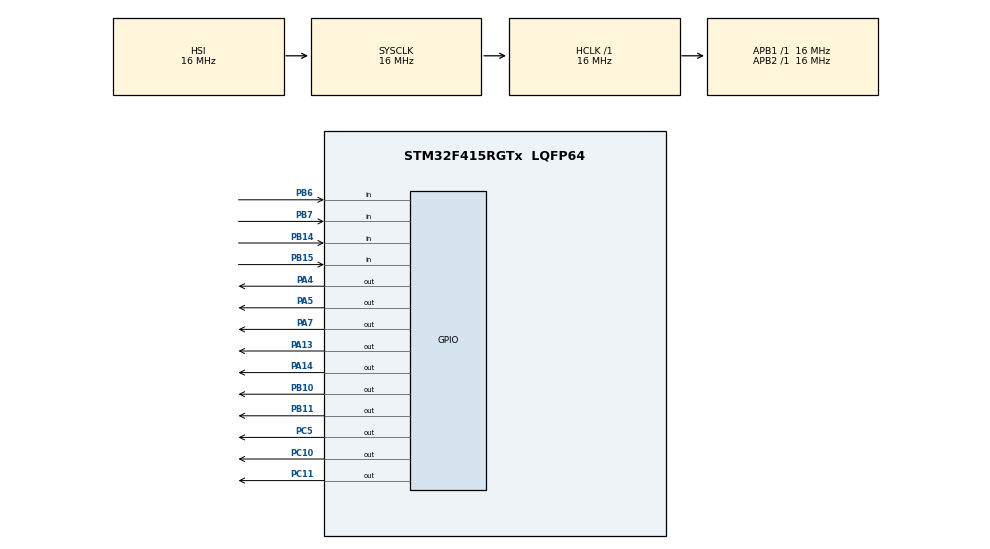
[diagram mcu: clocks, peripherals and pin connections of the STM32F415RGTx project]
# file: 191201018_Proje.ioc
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Mcu.Family=STM32F4
Mcu.Name=STM32F415RGTx
Mcu.Package=LQFP64
NVIC.PriorityGroup=NVIC_PRIORITYGROUP_4
NVIC.TIM3_IRQn=true\:0\:0\:false\:false\:true\:true\:true\:true
PA13.Signal=GPIO_Output
PA14.Signal=GPIO_Output
PA4.Signal=GPIO_Output
PA5.Signal=GPIO_Output
PA7.Signal=GPIO_Output
PB10.Signal=GPIO_Output
PB11.Signal=GPIO_Output
PB14.Signal=GPIO_Input
PB15.Signal=GPIO_Input
PB6.Signal=GPIO_Input
PB7.Signal=GPIO_Input
PC10.Signal=GPIO_Output
PC11.Signal=GPIO_Output
PC5.Signal=GPIO_Output
ProjectManager.HeapSize=0x200
ProjectManager.StackSize=0x400
ProjectManager.TargetToolchain=MDK-ARM V5.27
RCC.AHBFreq_Value=16000000
RCC.APB1Freq_Value=16000000
RCC.APB2Freq_Value=16000000
RCC.CortexFreq_Value=16000000
RCC.HSE_VALUE=25000000
RCC.HSI_VALUE=16000000
RCC.LSE_VALUE=32768
RCC.SYSCLKFreq_VALUE=16000000
RCC.VCOOutputFreq_Value=192000000
TIM3.Period=15999
TIM3.Prescaler=15999
VP_TIM3_VS_ClockSourceINT.Mode=Internal
board=custom

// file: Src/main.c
/* USER CODE BEGIN Header */
/**
 ******************************************************************************
 * @file           : main.c
 * @brief          : Main program body
 ******************************************************************************
 * @attention
 *
 * Copyright (c) 2022 STMicroelectronics.
 * All rights reserved.
 *
 * This software is licensed under terms that can be found in the LICENSE file
 * in the root directory of this software component.
 * If no LICENSE file comes with this software, it is provided AS-IS.
 *
 ******************************************************************************
 */
/* USER CODE END Header */
#include "main.h"

/* USER CODE BEGIN Includes */
#include <stdio.h>
#include <stdlib.h>
#include <stdint.h>
#include <time.h>
#include "Nokia_5110.h"
/* USER CODE END Includes */

/* USER CODE BEGIN PD */
#define R1_PORT GPIOB
#define R2_PORT GPIOB
#define R3_PORT GPIOB
#define R4_PORT GPIOB
#define R1_PIN GPIO_PIN_6
#define R2_PIN GPIO_PIN_7
#define R3_PIN GPIO_PIN_15
#define R4_PIN GPIO_PIN_14

#define C1_PORT GPIOB
#define C2_PORT GPIOB
#define C3_PORT GPIOC
#define C4_PORT GPIOC
#define C1_PIN GPIO_PIN_11
#define C2_PIN GPIO_PIN_10
#define C3_PIN GPIO_PIN_11
#define C4_PIN GPIO_PIN_10
/* USER CODE END PD */

TIM_HandleTypeDef htim3;

/* USER CODE BEGIN PV */

// #region Visuals

const unsigned char Screen_Start_Bitmap[] = {
    0x00, 0x00, 0x00, 0x00, 0x00, 0x00, 0x00, 0x00, 0x00, 0x00, 0x00, 0x00, 0x00, 0x00, 0x00, 0x00, 0x00, 0x00, 0x00, 0x00, 0x00, 0x00, 0x00, 0x00, 0x00, 0x00, 0x00, 0x00, 0x00, 0x00, 0x00, 0x00, 0x00, 0x00, 0x00, 0x00, 0x00, 0x00, 0x00, 0x00, 0x00, 0x00, 0x00, 0x00, 0x00, 0x00, 0x00, 0x00, 0x00, 0x00, 0x00, 0x00, 0x00, 0x00, 0x00, 0x00, 0x00, 0x00, 0x00, 0x00, 0x00, 0x00, 0x00, 0x00, 0x00, 0x00, 0x00, 0x00, 0x00, 0x00, 0x00, 0x00, 0x00, 0x00, 0x00, 0x00, 0x00, 0x00, 0x00, 0x00, 0x00, 0x00, 0x00, 0x00,
    0x00, 0x00, 0x00, 0x00, 0x00, 0x00, 0x00, 0x18, 0x18, 0xd8, 0xd8, 0xd8, 0xf8, 0x00, 0x20, 0xf8, 0x98, 0x98, 0x98, 0x88, 0x80, 0x00, 0x00, 0x98, 0x98, 0x98, 0x98, 0x98, 0xf8, 0x10, 0x00, 0x00, 0x00, 0x00, 0x00, 0x00, 0x00, 0x00, 0xf8, 0xd8, 0xd8, 0x98, 0xd8, 0xd8, 0x00, 0x00, 0xc0, 0x00, 0x00, 0xc0, 0x00, 0x00, 0xc0, 0xc0, 0x40, 0xc0, 0x00, 0x20, 0xf8, 0x98, 0x18, 0x00, 0xc0, 0xc0, 0xc0, 0xc0, 0x00, 0x00, 0xc0, 0xc0, 0xc0, 0xc0, 0x00, 0x00, 0xc0, 0xc0, 0xc0, 0x80, 0x00, 0x00, 0x00, 0x00, 0x00, 0x00,
    0x00, 0x00, 0x00, 0x00, 0x00, 0x00, 0x00, 0x0c, 0x0c, 0x0c, 0x04, 0x0c, 0x0f, 0x00, 0x02, 0x0f, 0x0d, 0x0d, 0x09, 0x0d, 0x0f, 0x00, 0x02, 0x0f, 0x0d, 0x0d, 0x05, 0x0d, 0x0d, 0x00, 0x00, 0x00, 0x00, 0x00, 0x00, 0x00, 0x00, 0x00, 0x0c, 0x08, 0x0c, 0x0c, 0x0d, 0x0f, 0x00, 0x00, 0x0f, 0x0c, 0x0c, 0x0f, 0x01, 0x00, 0x0f, 0x01, 0x00, 0x00, 0x00, 0x00, 0x0f, 0x01, 0x00, 0x00, 0x0f, 0x0f, 0x0f, 0x0f, 0x00, 0x00, 0x0f, 0x00, 0x00, 0x00, 0x00, 0x00, 0x0f, 0x0f, 0x0f, 0x0f, 0x00, 0x00, 0x00, 0x00, 0x00, 0x00,
    0x00, 0x00, 0x00, 0x00, 0x00, 0x00, 0x00, 0x00, 0x00, 0x00, 0x00, 0x00, 0x00, 0x00, 0x00, 0x00, 0x00, 0x00, 0x00, 0x00, 0xc0, 0xc0, 0xc0, 0xc0, 0xc0, 0x00, 0x00, 0xc0, 0xc0, 0xc0, 0xc0, 0x00, 0x00, 0xc0, 0xc0, 0xc0, 0xc0, 0x00, 0x00, 0xc0, 0xc0, 0x80, 0xc0, 0x00, 0x00, 0xc0, 0x40, 0xc0, 0xc0, 0x00, 0x00, 0x00, 0x00, 0xf8, 0x98, 0xd8, 0xd8, 0xd8, 0x00, 0x00, 0x00, 0x00, 0x00, 0x00, 0x00, 0x00, 0x00, 0x00, 0x00, 0x00, 0x00, 0x00, 0x00, 0x00, 0x00, 0x00, 0x00, 0x00, 0x00, 0x00, 0x00, 0x00, 0x00, 0x00,
    0x00, 0x00, 0x00, 0x00, 0x00, 0x00, 0x00, 0x00, 0x00, 0x00, 0x00, 0x00, 0x00, 0x00, 0x00, 0x00, 0x00, 0x00, 0x00, 0x00, 0xff, 0x1c, 0x0c, 0x08, 0x0f, 0x04, 0x01, 0x0f, 0x00, 0x00, 0x00, 0x00, 0x02, 0x0f, 0x0d, 0x0f, 0x0f, 0x00, 0x00, 0x0f, 0x0d, 0x0f, 0x0f, 0x00, 0x00, 0x0f, 0x0f, 0x0d, 0x0f, 0x00, 0x00, 0x00, 0x00, 0x0c, 0x0c, 0x0c, 0x0c, 0x0f, 0x00, 0x00, 0x00, 0x00, 0x00, 0x00, 0x00, 0x00, 0x00, 0x00, 0x00, 0x00, 0x00, 0x00, 0x00, 0x00, 0x00, 0x00, 0x00, 0x00, 0x00, 0x00, 0x00, 0x00, 0x00, 0x00,
    0x00, 0x00, 0x00, 0x00, 0x00, 0x00, 0x00, 0x00, 0x00, 0x00, 0x00, 0x00, 0x00, 0x00, 0x00, 0x00, 0x00, 0x00, 0x00, 0x00, 0x00, 0x00, 0x00, 0x00, 0x00, 0x00, 0x00, 0x00, 0x00, 0x00, 0x00, 0x00, 0x00, 0x00, 0x00, 0x00, 0x00, 0x00, 0x00, 0x00, 0x00, 0x00, 0x00, 0x00, 0x00, 0x00, 0x00, 0x00, 0x00, 0x00, 0x00, 0x00, 0x00, 0x00, 0x00, 0x00, 0x00, 0x00, 0x00, 0x00, 0x00, 0x00, 0x00, 0x00, 0x00, 0x00, 0x00, 0x00, 0x00, 0x00, 0x00, 0x00, 0x00, 0x00, 0x00, 0x00, 0x00, 0x00, 0x00, 0x00, 0x00, 0x00, 0x00, 0x00};

const unsigned char Screen_End_Fail_Bitmap[] = {
    0x00, 0x00, 0x00, 0x00, 0x00, 0x00, 0x00, 0x00, 0x00, 0x00, 0x00, 0x00, 0x00, 0x00, 0x00, 0x00, 0x00, 0x00, 0x00, 0x00, 0x00, 0x00, 0x00, 0x00, 0x00, 0x00, 0x00, 0x00, 0x00, 0x00, 0x00, 0x00, 0x00, 0x00, 0x00, 0x00, 0x00, 0x00, 0x00, 0x00, 0x00, 0x00, 0x00, 0x00, 0x00, 0x00, 0x00, 0x00, 0x00, 0x00, 0x00, 0x00, 0x00, 0x00, 0x00, 0x00, 0x00, 0x00, 0x00, 0x00, 0x00, 0x00, 0x00, 0x00, 0x00, 0x00, 0x00, 0x00, 0x00, 0x00, 0x00, 0x00, 0x00, 0x00, 0x00, 0x00, 0x00, 0x00, 0x00, 0x00, 0x00, 0x00, 0x00, 0x00,
    0x00, 0x00, 0x00, 0x00, 0x00, 0x00, 0x00, 0x00, 0x00, 0x00, 0x00, 0x00, 0x00, 0x00, 0x00, 0x00, 0x00, 0x00, 0x00, 0x00, 0x00, 0x00, 0x00, 0x00, 0x00, 0xb8, 0xa8, 0x08, 0x08, 0x08, 0x98, 0xf0, 0x00, 0xb8, 0xe8, 0x08, 0x08, 0x08, 0xd8, 0x68, 0x00, 0xb8, 0xe8, 0x08, 0x08, 0x08, 0xd8, 0x68, 0x00, 0xb8, 0xa8, 0x08, 0x08, 0x08, 0x08, 0x08, 0x00, 0x58, 0xb8, 0x00, 0x00, 0x00, 0x00, 0x00, 0x00, 0x00, 0x00, 0x00, 0x00, 0x00, 0x00, 0x00, 0x00, 0x00, 0x00, 0x00, 0x00, 0x00, 0x00, 0x00, 0x00, 0x00, 0x00, 0x00,
    0x00, 0x00, 0x00, 0x00, 0x00, 0x00, 0x00, 0x00, 0x00, 0x00, 0x00, 0x00, 0x00, 0x00, 0x00, 0x00, 0x00, 0x00, 0x00, 0x00, 0x00, 0x00, 0x00, 0x00, 0x00, 0x17, 0x1e, 0x10, 0x10, 0x10, 0x17, 0x1c, 0x00, 0x17, 0x1d, 0x10, 0x10, 0x10, 0x19, 0x1d, 0x00, 0x1e, 0x0f, 0x01, 0x01, 0x01, 0x01, 0x01, 0x00, 0x11, 0x11, 0x11, 0x11, 0x11, 0x1b, 0x1f, 0x00, 0x16, 0x13, 0x00, 0x00, 0x00, 0x00, 0x00, 0x00, 0x00, 0x00, 0x00, 0x00, 0x00, 0x00, 0x00, 0x00, 0x00, 0x00, 0x00, 0x00, 0x00, 0x00, 0x00, 0x00, 0x00, 0x00, 0x00,
    0x00, 0x00, 0x00, 0x00, 0x00, 0x00, 0x00, 0x00, 0x00, 0x00, 0x00, 0x00, 0x00, 0x00, 0xf8, 0x80, 0x80, 0x80, 0x80, 0xf8, 0x00, 0x00, 0xc0, 0x40, 0x40, 0x40, 0x40, 0xc0, 0x00, 0x00, 0xc0, 0x00, 0x00, 0x00, 0x00, 0xc0, 0x00, 0x00, 0x00, 0x00, 0x00, 0x00, 0xc0, 0x40, 0x40, 0x40, 0x40, 0xf8, 0x00, 0x00, 0xc8, 0x00, 0x00, 0xc0, 0x40, 0x40, 0x40, 0xc0, 0x00, 0x00, 0xc0, 0x40, 0x40, 0x40, 0x40, 0xf8, 0x00, 0x00, 0x00, 0x00, 0x00, 0x00, 0x00, 0x00, 0x00, 0x00, 0x00, 0x00, 0x00, 0x00, 0x00, 0x00, 0x00, 0x00,
    0x00, 0x00, 0x00, 0x00, 0x00, 0x00, 0x00, 0x00, 0x00, 0x00, 0x00, 0x00, 0x00, 0x00, 0x08, 0x08, 0x08, 0x08, 0x08, 0x0f, 0x00, 0x00, 0x0f, 0x08, 0x08, 0x08, 0x08, 0x0f, 0x00, 0x00, 0x0f, 0x08, 0x08, 0x08, 0x08, 0x0f, 0x00, 0x00, 0x00, 0x00, 0x00, 0x00, 0x0f, 0x08, 0x08, 0x08, 0x08, 0x0f, 0x00, 0x00, 0x0f, 0x00, 0x00, 0x0f, 0x09, 0x09, 0x09, 0x09, 0x00, 0x00, 0x0f, 0x08, 0x08, 0x08, 0x08, 0x0f, 0x00, 0x00, 0x0c, 0x0c, 0x00, 0x00, 0x00, 0x00, 0x00, 0x00, 0x00, 0x00, 0x00, 0x00, 0x00, 0x00, 0x00, 0x00,
    0x00, 0x00, 0x00, 0x00, 0x00, 0x00, 0x00, 0x00, 0x00, 0x00, 0x00, 0x00, 0x00, 0x00, 0x00, 0x00, 0x00, 0x00, 0x00, 0x00, 0x00, 0x00, 0x00, 0x00, 0x00, 0x00, 0x00, 0x00, 0x00, 0x00, 0x00, 0x00, 0x00, 0x00, 0x00, 0x00, 0x00, 0x00, 0x00, 0x00, 0x00, 0x00, 0x00, 0x00, 0x00, 0x00, 0x00, 0x00, 0x00, 0x00, 0x00, 0x00, 0x00, 0x00, 0x00, 0x00, 0x00, 0x00, 0x00, 0x00, 0x00, 0x00, 0x00, 0x00, 0x00, 0x00, 0x00, 0x00, 0x00, 0x00, 0x00, 0x00, 0x00, 0x00, 0x00, 0x00, 0x00, 0x00, 0x00, 0x00, 0x00, 0x00, 0x00, 0x00};

const unsigned char Screen_End_Success_Bitmap[] = {
    0x00, 0x00, 0x00, 0x00, 0x00, 0x00, 0x00, 0x00, 0x00, 0x00, 0x00, 0x00, 0x00, 0x00, 0x00, 0x00, 0x00, 0x00, 0x00, 0x00, 0x00, 0x00, 0x00, 0x00, 0x00, 0x00, 0x00, 0x00, 0x00, 0x00, 0x00, 0x00, 0x00, 0x00, 0x00, 0x00, 0x00, 0x00, 0x00, 0x00, 0x00, 0x00, 0x00, 0x00, 0x00, 0x00, 0x00, 0x00, 0x00, 0x00, 0x00, 0x00, 0x00, 0x00, 0x00, 0x00, 0x00, 0x00, 0x00, 0x00, 0x00, 0x00, 0x00, 0x00, 0x00, 0x00, 0x00, 0x00, 0x00, 0x00, 0x00, 0x00, 0x00, 0x00, 0x00, 0x00, 0x00, 0x00, 0x00, 0x00, 0x00, 0x00, 0x00, 0x00,
    0x00, 0x00, 0x00, 0x00, 0x00, 0x00, 0x00, 0x00, 0x00, 0x00, 0x00, 0x00, 0xff, 0xdf, 0x00, 0x00, 0x00, 0x00, 0x00, 0x00, 0x00, 0x00, 0x00, 0x00, 0x00, 0x00, 0x00, 0xff, 0xff, 0x00, 0x00, 0x00, 0x00, 0x00, 0x00, 0x00, 0x00, 0x00, 0x00, 0x00, 0x00, 0x00, 0x00, 0x00, 0x00, 0x00, 0x00, 0x00, 0xff, 0xf7, 0x00, 0x00, 0x00, 0x00, 0x00, 0x00, 0x00, 0x00, 0x00, 0x00, 0x00, 0x00, 0x00, 0xff, 0xff, 0x00, 0x00, 0x00, 0x00, 0xff, 0xff, 0x00, 0x00, 0x00, 0x00, 0x00, 0x00, 0x00, 0x00, 0x00, 0x00, 0x00, 0x00, 0x00,
    0x00, 0x00, 0x00, 0x00, 0x00, 0x00, 0x00, 0x00, 0x00, 0x00, 0x00, 0x00, 0xff, 0x77, 0x00, 0x00, 0x00, 0x00, 0x00, 0x00, 0x00, 0x00, 0x00, 0x00, 0x00, 0x00, 0x00, 0xff, 0xff, 0x00, 0x00, 0x00, 0xff, 0xff, 0x03, 0x01, 0x03, 0x01, 0x03, 0x01, 0x03, 0x01, 0x01, 0xff, 0xff, 0x00, 0x00, 0x00, 0xff, 0xdd, 0x00, 0x00, 0x00, 0x00, 0x00, 0x00, 0x00, 0x00, 0x00, 0x00, 0x00, 0x00, 0x00, 0xff, 0xff, 0x00, 0x00, 0x00, 0x00, 0xff, 0xff, 0x00, 0x00, 0x00, 0x00, 0x00, 0x00, 0x00, 0x00, 0x00, 0x00, 0x00, 0x00, 0x00,
    0x00, 0x00, 0x00, 0x00, 0x00, 0x00, 0x00, 0x00, 0x00, 0x00, 0x00, 0x00, 0xfe, 0x7f, 0x00, 0x00, 0x00, 0x00, 0x00, 0xfc, 0xfc, 0xfc, 0x40, 0x00, 0x00, 0x00, 0x00, 0xff, 0xff, 0x00, 0x00, 0x00, 0xff, 0x7d, 0x00, 0x00, 0x00, 0x00, 0x00, 0x00, 0x00, 0x00, 0x00, 0xff, 0xff, 0x00, 0x00, 0x00, 0xdf, 0xff, 0x00, 0x00, 0x00, 0x00, 0x00, 0xfc, 0xfc, 0xfc, 0x00, 0x00, 0x00, 0x00, 0x00, 0xff, 0xff, 0x00, 0x00, 0x00, 0x00, 0xff, 0xff, 0x00, 0x00, 0x00, 0x00, 0x00, 0x00, 0x00, 0x00, 0x00, 0x00, 0x00, 0x00, 0x00,
    0x00, 0x00, 0x00, 0x00, 0x00, 0x00, 0x00, 0x00, 0x00, 0x00, 0x00, 0x00, 0xff, 0xff, 0x80, 0xc0, 0x80, 0xc0, 0x88, 0xff, 0xff, 0xff, 0x90, 0xc0, 0x80, 0xc0, 0x80, 0xff, 0xff, 0x00, 0x00, 0x00, 0xff, 0xf7, 0xc0, 0x80, 0x80, 0xc0, 0x80, 0x80, 0xc0, 0x80, 0x80, 0xff, 0xff, 0x00, 0x00, 0x00, 0xff, 0xdf, 0x80, 0xc0, 0x80, 0xc0, 0x80, 0xff, 0xff, 0xff, 0xc4, 0x80, 0x80, 0xc0, 0x80, 0xff, 0xff, 0x00, 0x00, 0x00, 0x00, 0xf3, 0xf3, 0x00, 0x00, 0x00, 0x00, 0x00, 0x00, 0x00, 0x00, 0x00, 0x00, 0x00, 0x00, 0x00,
    0x00, 0x00, 0x00, 0x00, 0x00, 0x00, 0x00, 0x00, 0x00, 0x00, 0x00, 0x00, 0x00, 0x00, 0x00, 0x00, 0x00, 0x00, 0x00, 0x00, 0x00, 0x00, 0x00, 0x00, 0x00, 0x00, 0x00, 0x00, 0x00, 0x00, 0x00, 0x00, 0x00, 0x00, 0x00, 0x00, 0x00, 0x00, 0x00, 0x00, 0x00, 0x00, 0x00, 0x00, 0x00, 0x00, 0x00, 0x00, 0x00, 0x00, 0x00, 0x00, 0x00, 0x00, 0x00, 0x00, 0x01, 0x00, 0x00, 0x00, 0x00, 0x00, 0x00, 0x00, 0x00, 0x00, 0x00, 0x00, 0x00, 0x00, 0x00, 0x00, 0x00, 0x00, 0x00, 0x00, 0x00, 0x00, 0x00, 0x00, 0x00, 0x00, 0x00, 0x00};

// To animate success, first clear the screen, then draw the success image. Then, animate the success image by shifting it to the left and drawing it again.

const unsigned char Barrier_Jump_Bitmap[] = {
    0x00, 0x00, 0x00, 0x00, 0x00, 0x00, 0x00, 0x00, 0x00, 0x00, 0x00, 0x00, 0x00, 0xe7, 0xe7, 0x00, 0x00, 0x00, 0x00, 0x00, 0x00, 0x00, 0x00, 0x00, 0x00, 0x00, 0x00, 0x00};

const unsigned char Barrier_Solid_Bitmap[] = {
    0x00, 0x00, 0x00, 0x00, 0x00, 0x00, 0x00, 0x00, 0x00, 0x00, 0x00, 0x00, 0x00, 0xff, 0xff, 0x00, 0x00, 0x00, 0x00, 0x00, 0x00, 0x00, 0x00, 0x00, 0x00, 0x00, 0x00, 0x00};

const unsigned char Empty_Bitmap[] = {
    0x00, 0x00, 0x00, 0x00, 0x00, 0x00, 0x00, 0x00, 0x00, 0x00, 0x00, 0x00, 0x00, 0x00, 0x00, 0x00, 0x00, 0x00, 0x00, 0x00, 0x00, 0x00, 0x00, 0x00, 0x00, 0x00, 0x00, 0x00};

const unsigned char Empty_Row_Bitmap[] = {
    0x00, 0x00, 0x00, 0x00, 0x00, 0x00, 0x00, 0x00, 0x00, 0x00, 0x00, 0x00, 0x00, 0x00, 0x00, 0x00, 0x00, 0x00, 0x00, 0x00, 0x00, 0x00, 0x00, 0x00, 0x00, 0x00, 0x00, 0x00,
    0x00, 0x00, 0x00, 0x00, 0x00, 0x00, 0x00, 0x00, 0x00, 0x00, 0x00, 0x00, 0x00, 0x00, 0x00, 0x00, 0x00, 0x00, 0x00, 0x00, 0x00, 0x00, 0x00, 0x00, 0x00, 0x00, 0x00, 0x00,
    0x00, 0x00, 0x00, 0x00, 0x00, 0x00, 0x00, 0x00, 0x00, 0x00, 0x00, 0x00, 0x00, 0x00, 0x00, 0x00, 0x00, 0x00, 0x00, 0x00, 0x00, 0x00, 0x00, 0x00, 0x00, 0x00, 0x00, 0x00};

const unsigned char Player_Default_Bitmap[] = {
    0x00, 0x00, 0x00, 0x00, 0x00, 0x00, 0x00, 0x00, 0x00, 0x40, 0x60, 0x30, 0x18, 0x0c, 0x0c, 0x18, 0x30, 0x60, 0x40, 0x00, 0x00, 0x00, 0x00, 0x00, 0x00, 0x00, 0x00, 0x00};

const unsigned char Player_Jump_Bitmap[] = {
    0x00, 0x00, 0x00, 0x00, 0x40, 0x60, 0x30, 0x18, 0x0c, 0x00, 0x00, 0x00, 0x00, 0xe7, 0xe7, 0x00, 0x00, 0x00, 0x00, 0x0c, 0x18, 0x30, 0x60, 0x40, 0x00, 0x00, 0x00, 0x00};

/*ANIMATIONS*/
const unsigned char ETU_1[] = {
    0x00, 0x00, 0x00, 0x00, 0x00, 0x00, 0x00, 0x00, 0x00, 0x00, 0x00, 0x00, 0x00, 0x00, 0x00, 0x00, 0x00, 0x00, 0x00, 0x00, 0x00, 0x00, 0x00, 0x00, 0x00, 0x00, 0x00, 0x00, 0x00, 0x00, 0x00, 0x80, 0x00, 0x00, 0x20, 0x20, 0x00, 0x90, 0x80, 0x10, 0xd0, 0x00, 0x90, 0x00, 0x00, 0xd0, 0x00, 0x20, 0x20, 0x00, 0x40, 0x00, 0x80, 0x00, 0x00, 0x00, 0x00, 0x00, 0x00, 0x00, 0x00, 0x00, 0x00, 0x00, 0x00, 0x00, 0x00, 0x00, 0x00, 0x00, 0x00, 0x00, 0x00, 0x00, 0x00, 0x00, 0x00, 0x00, 0x00, 0x00, 0x00, 0x00, 0x00, 0x00,
    0x00, 0x00, 0x00, 0x00, 0x00, 0x00, 0x00, 0x00, 0x00, 0x00, 0x00, 0x00, 0x00, 0x00, 0x00, 0x00, 0x00, 0x00, 0x00, 0x00, 0x00, 0x00, 0x00, 0x00, 0x40, 0x10, 0x08, 0x04, 0x00, 0x43, 0x00, 0x00, 0x86, 0x0e, 0x07, 0x20, 0x17, 0x03, 0x02, 0x0b, 0x0a, 0x00, 0x03, 0x08, 0x0b, 0x01, 0x00, 0x16, 0x03, 0x0c, 0x97, 0x00, 0x02, 0x00, 0x42, 0x02, 0x00, 0x08, 0x20, 0x40, 0x00, 0x00, 0x00, 0x00, 0x00, 0x00, 0x00, 0x00, 0x00, 0x00, 0x00, 0x00, 0x00, 0x00, 0x00, 0x00, 0x00, 0x00, 0x00, 0x00, 0x00, 0x00, 0x00, 0x00,
    0x00, 0x00, 0x00, 0x00, 0x00, 0x00, 0x00, 0x00, 0x00, 0x00, 0x00, 0x00, 0x00, 0x00, 0x00, 0x00, 0x00, 0x00, 0x00, 0x00, 0x00, 0x00, 0xa8, 0x02, 0x00, 0xd8, 0x52, 0x10, 0x00, 0x60, 0x0c, 0x02, 0x00, 0x00, 0x00, 0x00, 0x00, 0x80, 0xe0, 0xfe, 0xff, 0x3f, 0x3f, 0xff, 0xfc, 0xe0, 0x80, 0x00, 0x00, 0x00, 0x00, 0x00, 0x02, 0x08, 0x60, 0x00, 0x00, 0xaa, 0xa8, 0x00, 0x06, 0xa0, 0x00, 0x00, 0x00, 0x00, 0x00, 0x00, 0x00, 0x00, 0x00, 0x00, 0x00, 0x00, 0x00, 0x00, 0x00, 0x00, 0x00, 0x00, 0x00, 0x00, 0x00, 0x00,
    0x00, 0x00, 0x00, 0x00, 0x00, 0x00, 0x00, 0x00, 0x00, 0x00, 0x00, 0x00, 0x00, 0x00, 0x00, 0x00, 0x00, 0x00, 0x00, 0x00, 0x00, 0x00, 0x16, 0x40, 0x00, 0x29, 0x75, 0x80, 0x00, 0x06, 0x20, 0x40, 0x00, 0x00, 0x08, 0x3e, 0x3f, 0x1f, 0x3b, 0x1b, 0x10, 0x1c, 0x18, 0x18, 0x2b, 0x3b, 0x1f, 0x7f, 0x3e, 0x3c, 0x00, 0x00, 0x80, 0x10, 0x03, 0x00, 0x60, 0x15, 0x05, 0x00, 0x80, 0x16, 0x00, 0x00, 0x00, 0x00, 0x00, 0x00, 0x00, 0x00, 0x00, 0x00, 0x00, 0x00, 0x00, 0x00, 0x00, 0x00, 0x00, 0x00, 0x00, 0x00, 0x00, 0x00,
    0x00, 0x00, 0x00, 0x00, 0x00, 0x00, 0x00, 0x00, 0x00, 0x00, 0x00, 0x00, 0x00, 0x00, 0x00, 0x00, 0x00, 0x00, 0x00, 0x00, 0x00, 0x00, 0x00, 0x00, 0x03, 0x00, 0x10, 0x00, 0x41, 0x04, 0x10, 0x08, 0x00, 0x01, 0x60, 0x94, 0x00, 0xc8, 0x00, 0x91, 0x91, 0x02, 0x91, 0x02, 0xc3, 0x80, 0x00, 0xc8, 0xc4, 0x40, 0x01, 0x24, 0x28, 0x01, 0x84, 0x42, 0x21, 0x00, 0x04, 0x01, 0x00, 0x00, 0x00, 0x00, 0x00, 0x00, 0x00, 0x00, 0x00, 0x00, 0x00, 0x00, 0x00, 0x00, 0x00, 0x00, 0x00, 0x00, 0x00, 0x00, 0x00, 0x00, 0x00, 0x00,
    0x00, 0x00, 0x00, 0x00, 0x00, 0x00, 0x00, 0x00, 0x00, 0x00, 0x00, 0x00, 0x00, 0x00, 0x00, 0x00, 0x00, 0x00, 0x00, 0x00, 0x00, 0x00, 0x00, 0x00, 0x00, 0x00, 0x00, 0x00, 0x00, 0x00, 0x00, 0x01, 0x02, 0x00, 0x00, 0x04, 0x04, 0x00, 0x09, 0x00, 0x08, 0x01, 0x09, 0x08, 0x09, 0x00, 0x08, 0x00, 0x04, 0x04, 0x02, 0x00, 0x01, 0x00, 0x00, 0x00, 0x00, 0x00, 0x00, 0x00, 0x00, 0x00, 0x00, 0x00, 0x00, 0x00, 0x00, 0x00, 0x00, 0x00, 0x00, 0x00, 0x00, 0x00, 0x00, 0x00, 0x00, 0x00, 0x00, 0x00, 0x00, 0x00, 0x00, 0x00};

const unsigned char ETU_2[] = {
    0x00, 0x00, 0x00, 0x00, 0x00, 0x00, 0x00, 0x00, 0x00, 0x00, 0x00, 0x00, 0x00, 0x00, 0x00, 0x00, 0x00, 0xc0, 0x20, 0x10, 0x08, 0x04, 0x82, 0xc1, 0xc0, 0x80, 0x18, 0xa0, 0x40, 0x00, 0x00, 0x80, 0x06, 0x82, 0x40, 0x40, 0x00, 0x20, 0x20, 0x24, 0x07, 0x20, 0x23, 0x25, 0x24, 0x26, 0x03, 0x47, 0x4b, 0x0d, 0x85, 0x98, 0x0e, 0xb7, 0x15, 0x86, 0xc0, 0x60, 0x70, 0x11, 0x21, 0x42, 0x84, 0x08, 0x10, 0x40, 0x80, 0x00, 0x00, 0x00, 0x00, 0x00, 0x00, 0x00, 0x00, 0x00, 0x00, 0x00, 0x00, 0x00, 0x00, 0x00, 0x00, 0x00,
    0x00, 0x00, 0x00, 0x00, 0x00, 0x00, 0x00, 0x00, 0x00, 0x00, 0x00, 0x00, 0x00, 0xc0, 0x18, 0x04, 0x03, 0x00, 0xc0, 0x50, 0x54, 0x2a, 0x0a, 0x00, 0x00, 0x81, 0x21, 0x10, 0x08, 0x04, 0x02, 0x01, 0x01, 0x00, 0x00, 0x00, 0x00, 0x00, 0x00, 0x00, 0x00, 0x00, 0x80, 0xe0, 0xe0, 0xe0, 0xe0, 0xe0, 0xc0, 0x80, 0x00, 0x00, 0x01, 0x02, 0x00, 0x08, 0x11, 0x61, 0x85, 0x04, 0x06, 0x73, 0x11, 0x5b, 0x0c, 0x28, 0x14, 0x03, 0x04, 0x60, 0x80, 0x00, 0x00, 0x00, 0x00, 0x00, 0x00, 0x00, 0x00, 0x00, 0x00, 0x00, 0x00, 0x00,
    0x00, 0x00, 0x00, 0x00, 0x00, 0x00, 0x00, 0x00, 0x00, 0x00, 0x00, 0x00, 0xbc, 0x01, 0x00, 0x00, 0xe8, 0x2a, 0x6a, 0x09, 0x00, 0x00, 0x00, 0x78, 0x06, 0x00, 0x00, 0x00, 0x00, 0x80, 0xa0, 0x60, 0xe0, 0xf0, 0xf0, 0xf0, 0xf8, 0xf8, 0xfc, 0x7c, 0x3f, 0x3f, 0x1f, 0x1f, 0xff, 0xff, 0xff, 0xff, 0xff, 0x07, 0x00, 0x00, 0x00, 0x00, 0x00, 0x00, 0x00, 0x00, 0x00, 0x06, 0xf0, 0x00, 0x00, 0x00, 0x00, 0x30, 0x10, 0x00, 0x00, 0x00, 0x01, 0xfc, 0x00, 0x00, 0x00, 0x00, 0x00, 0x00, 0x00, 0x00, 0x00, 0x00, 0x00, 0x00,
    0x00, 0x00, 0x00, 0x00, 0x00, 0x00, 0x00, 0x00, 0x00, 0x00, 0x00, 0x00, 0x1e, 0xc0, 0x00, 0x00, 0x01, 0x21, 0x91, 0xa0, 0x80, 0x00, 0x00, 0x0f, 0x60, 0x00, 0x00, 0x00, 0x01, 0x07, 0x0a, 0x1f, 0x07, 0x1f, 0x16, 0x1d, 0x18, 0x3c, 0x78, 0xa8, 0xa0, 0xf0, 0xa0, 0xc0, 0xbf, 0xff, 0xff, 0xff, 0xfc, 0x80, 0x00, 0x00, 0x00, 0x00, 0x00, 0x00, 0x00, 0x00, 0x80, 0x40, 0x05, 0x00, 0x00, 0x88, 0xe0, 0x28, 0x28, 0x08, 0x00, 0x00, 0x80, 0x3d, 0x00, 0x00, 0x00, 0x00, 0x00, 0x00, 0x00, 0x00, 0x00, 0x00, 0x00, 0x00,
    0x00, 0x00, 0x00, 0x00, 0x00, 0x00, 0x00, 0x00, 0x00, 0x00, 0x00, 0x00, 0x00, 0x01, 0x0c, 0x20, 0xc0, 0x00, 0x00, 0x01, 0x21, 0x90, 0x58, 0x88, 0x90, 0x81, 0x84, 0x08, 0x10, 0x20, 0x40, 0x84, 0x88, 0x0a, 0x04, 0x1c, 0x28, 0x00, 0x70, 0x00, 0x01, 0x01, 0x02, 0x0f, 0x1c, 0x1f, 0x0f, 0x1f, 0x0f, 0x03, 0x01, 0x00, 0x80, 0x40, 0x20, 0x10, 0x08, 0x04, 0x01, 0x40, 0xa0, 0x50, 0xac, 0x2a, 0x0a, 0x02, 0x00, 0xc0, 0x18, 0x08, 0x01, 0x00, 0x00, 0x00, 0x00, 0x00, 0x00, 0x00, 0x00, 0x00, 0x00, 0x00, 0x00, 0x00,
    0x00, 0x00, 0x00, 0x00, 0x00, 0x00, 0x00, 0x00, 0x00, 0x00, 0x00, 0x00, 0x00, 0x00, 0x00, 0x00, 0x00, 0x01, 0x02, 0x08, 0x10, 0x20, 0x40, 0x82, 0x86, 0x07, 0x10, 0x0c, 0x10, 0x18, 0x50, 0x50, 0x20, 0xc1, 0x50, 0xc2, 0x02, 0xc2, 0x80, 0x24, 0xc4, 0x04, 0x04, 0x00, 0xc4, 0x14, 0xa0, 0x02, 0xc2, 0x21, 0xc1, 0x20, 0xc0, 0x10, 0x38, 0x04, 0x0a, 0x14, 0x03, 0x84, 0x00, 0x40, 0x28, 0x10, 0x08, 0x02, 0x01, 0x00, 0x00, 0x00, 0x00, 0x00, 0x00, 0x00, 0x00, 0x00, 0x00, 0x00, 0x00, 0x00, 0x00, 0x00, 0x00, 0x00};

const unsigned char ETU_3[] = {
    0x00, 0x00, 0x00, 0x00, 0x00, 0x00, 0x80, 0x60, 0x18, 0x04, 0x03, 0x00, 0x80, 0x00, 0x60, 0x48, 0x5a, 0x34, 0x0c, 0x09, 0x06, 0x02, 0x00, 0x00, 0xc0, 0x41, 0x21, 0x10, 0x08, 0x08, 0x04, 0x02, 0x02, 0x02, 0x01, 0x01, 0x01, 0x00, 0x00, 0x00, 0x80, 0x00, 0xc0, 0x80, 0x80, 0x80, 0x00, 0x00, 0x01, 0x01, 0x01, 0x02, 0x02, 0x04, 0x04, 0x08, 0x08, 0x10, 0x20, 0x50, 0x80, 0x00, 0x01, 0x00, 0x06, 0x42, 0x71, 0x2c, 0x90, 0x88, 0x20, 0x80, 0x80, 0x01, 0x03, 0x04, 0x10, 0x60, 0x80, 0x00, 0x00, 0x00, 0x00, 0x00,
    0x00, 0x00, 0x00, 0x80, 0x78, 0x06, 0x01, 0x20, 0x40, 0x40, 0xd8, 0x90, 0xa6, 0x25, 0x09, 0x02, 0x06, 0x02, 0x00, 0xc0, 0x30, 0x0c, 0x02, 0x01, 0x80, 0x00, 0x50, 0xa8, 0x74, 0x17, 0x08, 0x06, 0x00, 0x00, 0x00, 0x00, 0xc0, 0x60, 0x7a, 0xce, 0xbb, 0xad, 0x2f, 0xf1, 0xff, 0xfa, 0xff, 0xfc, 0xd4, 0x00, 0x00, 0x00, 0x00, 0x00, 0x00, 0x00, 0x00, 0x00, 0x00, 0x00, 0x00, 0x01, 0x06, 0x08, 0x30, 0xc0, 0x01, 0x04, 0x06, 0x03, 0x01, 0x01, 0x00, 0x00, 0x00, 0x00, 0x00, 0x02, 0x01, 0x0c, 0x70, 0x00, 0x00, 0x00,
    0x00, 0x00, 0xd0, 0x0f, 0x00, 0x00, 0x00, 0x00, 0xc0, 0x43, 0x42, 0x42, 0x42, 0x40, 0x01, 0x00, 0x40, 0xe0, 0x0f, 0x00, 0x00, 0x00, 0x00, 0x00, 0x01, 0x02, 0x02, 0x80, 0x00, 0xc0, 0xa0, 0xe0, 0x70, 0x68, 0xfc, 0x93, 0x7e, 0x0b, 0x1d, 0x05, 0x01, 0x00, 0x00, 0x0f, 0x7f, 0xff, 0xff, 0xff, 0xff, 0xf8, 0xe0, 0x80, 0x00, 0x00, 0x00, 0x00, 0x00, 0x00, 0x00, 0x00, 0x00, 0x00, 0x00, 0x00, 0x00, 0x01, 0x5e, 0x80, 0x00, 0x00, 0x00, 0x00, 0x01, 0x03, 0x03, 0x00, 0x00, 0x00, 0x00, 0x00, 0x00, 0xfe, 0x00, 0x00,
    0x00, 0x00, 0x1a, 0xc2, 0x00, 0x00, 0x00, 0x00, 0x12, 0x50, 0x5a, 0x58, 0x80, 0x02, 0x00, 0x01, 0x00, 0x8f, 0xe0, 0x00, 0x00, 0x00, 0x00, 0x00, 0x28, 0x7f, 0xfe, 0xff, 0xfd, 0xfb, 0xfe, 0xfe, 0xf9, 0xfd, 0xf9, 0xfc, 0xfc, 0xfc, 0xfc, 0xf8, 0xfc, 0xf8, 0xf8, 0xf8, 0xf0, 0xf1, 0xf3, 0xef, 0xff, 0xff, 0xff, 0xff, 0xfe, 0xfc, 0xf8, 0xf0, 0x00, 0x00, 0x00, 0x00, 0x00, 0x00, 0x00, 0x00, 0x00, 0x00, 0xf4, 0x03, 0x00, 0x00, 0xc8, 0x4c, 0x4c, 0x6c, 0xcc, 0xcc, 0xad, 0x1a, 0x00, 0x00, 0x00, 0xfd, 0x00, 0x00,
    0x00, 0x00, 0x00, 0x03, 0x1c, 0xe0, 0x00, 0x00, 0x00, 0x02, 0x01, 0x19, 0x9d, 0xc4, 0x40, 0x80, 0x00, 0x00, 0x01, 0x06, 0x18, 0x20, 0xc0, 0x00, 0x00, 0x00, 0x00, 0x00, 0x01, 0x03, 0x01, 0x01, 0x01, 0x01, 0x00, 0x00, 0x00, 0x00, 0x00, 0x01, 0x01, 0x01, 0x01, 0x01, 0x03, 0x03, 0x07, 0x0f, 0x0f, 0x1f, 0x0f, 0x0f, 0x0f, 0x07, 0x07, 0x03, 0x00, 0x00, 0x00, 0x00, 0x00, 0x80, 0x40, 0x30, 0x1c, 0x03, 0x00, 0xc0, 0xd8, 0x99, 0xb6, 0xf6, 0x6c, 0x6c, 0x6c, 0x04, 0x03, 0x00, 0x80, 0x60, 0x0e, 0x01, 0x00, 0x00,
    0x00, 0x00, 0x00, 0x00, 0x00, 0x00, 0x03, 0x0c, 0x31, 0x40, 0x80, 0x00, 0x01, 0x00, 0x09, 0x09, 0x44, 0x84, 0xf8, 0x10, 0x00, 0x80, 0x40, 0x01, 0x02, 0x04, 0x08, 0x10, 0x10, 0x20, 0x60, 0x40, 0x80, 0x80, 0x80, 0x00, 0x00, 0x00, 0x00, 0x00, 0x00, 0x00, 0x00, 0x00, 0x00, 0x00, 0x00, 0x00, 0x00, 0x00, 0x80, 0x80, 0x40, 0x40, 0x20, 0x20, 0x10, 0x18, 0x08, 0x84, 0x41, 0xe1, 0x80, 0x00, 0x0c, 0x1a, 0x13, 0x3e, 0x6c, 0x5d, 0x38, 0x09, 0x03, 0x01, 0x80, 0x60, 0x18, 0x06, 0x01, 0x00, 0x00, 0x00, 0x00, 0x00};

const unsigned char ETU_4[] = {
    0x00, 0x00, 0x80, 0x80, 0xc8, 0x88, 0x88, 0x48, 0x09, 0x1b, 0x03, 0x00, 0x04, 0x00, 0x40, 0x80, 0xc0, 0x20, 0x18, 0x0c, 0x06, 0x03, 0x01, 0x00, 0x00, 0x00, 0x00, 0x00, 0x00, 0x00, 0x00, 0x00, 0x00, 0x00, 0x00, 0x0f, 0x00, 0x09, 0x06, 0x09, 0x08, 0x07, 0x07, 0x08, 0x09, 0x07, 0x04, 0x0a, 0x09, 0x00, 0x00, 0x00, 0x00, 0x00, 0x00, 0x00, 0x00, 0x00, 0x00, 0x00, 0x00, 0x01, 0x01, 0x06, 0x04, 0x18, 0x24, 0xc0, 0x80, 0x00, 0x00, 0x00, 0x00, 0x30, 0x08, 0x08, 0xe4, 0x26, 0x36, 0x90, 0x90, 0x80, 0x00, 0x00,
    0x10, 0x10, 0x11, 0x30, 0xb5, 0x24, 0x03, 0x00, 0x00, 0x00, 0x00, 0x10, 0xe0, 0x38, 0x06, 0x03, 0x00, 0x00, 0x00, 0x00, 0x00, 0x00, 0x90, 0xfc, 0xfc, 0xfe, 0xff, 0xff, 0xff, 0xd5, 0x59, 0x6e, 0x76, 0xd8, 0xac, 0xb4, 0xc4, 0x78, 0x78, 0xc8, 0xb8, 0xa0, 0xd8, 0x78, 0x48, 0xf8, 0xa8, 0xb8, 0x5c, 0x74, 0xcc, 0xb2, 0xee, 0x5a, 0x5e, 0x73, 0x26, 0xfe, 0x5a, 0xd8, 0xf8, 0x00, 0x00, 0x00, 0x00, 0x00, 0x00, 0x00, 0x01, 0x06, 0x18, 0xe2, 0x80, 0x00, 0x00, 0x00, 0x00, 0x03, 0x09, 0xec, 0x24, 0x36, 0x26, 0xa0,
    0x49, 0x6c, 0x46, 0x63, 0x02, 0x60, 0x00, 0x00, 0x00, 0x10, 0x00, 0xfe, 0x01, 0x00, 0x00, 0x00, 0x00, 0x00, 0x00, 0x00, 0x00, 0x00, 0x02, 0x07, 0x0f, 0x0f, 0x3f, 0x7f, 0x7f, 0xff, 0xff, 0xff, 0xfe, 0xfc, 0xf8, 0xf1, 0xe1, 0x81, 0x01, 0x01, 0x02, 0x01, 0x03, 0x02, 0x01, 0x01, 0x81, 0xc1, 0xe1, 0xf9, 0xfc, 0xfc, 0xfe, 0xff, 0xff, 0xff, 0x7f, 0x1f, 0x1e, 0x0f, 0x05, 0x01, 0x00, 0x00, 0x00, 0x00, 0x00, 0x00, 0x00, 0x00, 0x00, 0x00, 0xbf, 0x40, 0x08, 0x00, 0x00, 0x00, 0x00, 0x00, 0x6d, 0x4d, 0x69, 0x4d,
    0x32, 0x12, 0xf3, 0x93, 0x42, 0x00, 0x00, 0x00, 0x00, 0x08, 0x00, 0xff, 0x80, 0x00, 0x00, 0x00, 0x00, 0x00, 0x00, 0x00, 0x00, 0x00, 0x00, 0x00, 0x00, 0x00, 0x00, 0x00, 0x00, 0x00, 0x03, 0x07, 0x1f, 0x7f, 0xff, 0xff, 0xff, 0xff, 0xff, 0xfc, 0xe0, 0x00, 0x00, 0xe0, 0xf8, 0xfe, 0xff, 0xff, 0xff, 0xff, 0xff, 0x1f, 0x0f, 0x03, 0x00, 0x00, 0x00, 0x00, 0x00, 0x00, 0x00, 0x00, 0x00, 0x00, 0x00, 0x00, 0x00, 0x00, 0x00, 0x00, 0x00, 0x00, 0xfc, 0x03, 0x10, 0x00, 0x00, 0x00, 0x00, 0x40, 0x9a, 0x13, 0x91, 0x93,
    0x05, 0x10, 0x98, 0xde, 0xc2, 0x44, 0x40, 0x20, 0x20, 0x00, 0x01, 0x00, 0x07, 0x18, 0xe0, 0x80, 0x00, 0x00, 0x00, 0x00, 0x00, 0x00, 0x00, 0x00, 0x00, 0x00, 0x00, 0x00, 0x00, 0x00, 0x00, 0x00, 0x00, 0x00, 0x03, 0xdf, 0xff, 0xff, 0xff, 0xff, 0xff, 0xfc, 0xff, 0xff, 0xff, 0xff, 0xff, 0xff, 0xff, 0x07, 0x00, 0x00, 0x00, 0x00, 0x00, 0x00, 0x00, 0x00, 0x00, 0x00, 0x00, 0x00, 0x00, 0x00, 0x00, 0x00, 0x00, 0x00, 0x80, 0xe0, 0x18, 0x47, 0x00, 0x04, 0x00, 0x60, 0x69, 0x43, 0xd2, 0xd2, 0x82, 0x87, 0x76, 0x06,
    0x00, 0x00, 0x01, 0x00, 0x00, 0x00, 0x00, 0x00, 0x00, 0x80, 0x80, 0x00, 0x00, 0x00, 0x00, 0x01, 0x06, 0x0c, 0x18, 0x30, 0x40, 0x80, 0x80, 0x00, 0x00, 0x00, 0x00, 0x00, 0x00, 0x00, 0x00, 0x00, 0x00, 0x00, 0x00, 0x00, 0x03, 0x03, 0x07, 0x07, 0x0f, 0x1f, 0x0f, 0x0f, 0x07, 0x07, 0x03, 0x03, 0x01, 0x00, 0x00, 0x00, 0x00, 0x00, 0x00, 0x00, 0x00, 0x00, 0x00, 0x00, 0x00, 0x80, 0x80, 0x40, 0x30, 0x10, 0x0c, 0x06, 0x01, 0x04, 0x00, 0x00, 0x00, 0x80, 0x80, 0x00, 0x00, 0x00, 0x00, 0x00, 0x00, 0x01, 0x00, 0x00};

const unsigned char ETU_5[] = {
    0x00, 0x00, 0x00, 0x00, 0x00, 0x00, 0x00, 0x00, 0x00, 0x00, 0x00, 0x00, 0x00, 0x00, 0x00, 0x00, 0x00, 0x00, 0x00, 0x00, 0x00, 0x00, 0x00, 0x00, 0x00, 0x80, 0x80, 0xc0, 0xe0, 0x80, 0x00, 0xe0, 0xc0, 0xc0, 0xc0, 0x80, 0x80, 0x80, 0x00, 0x00, 0x00, 0x00, 0x00, 0x00, 0x00, 0x00, 0x00, 0x00, 0x80, 0x80, 0x80, 0xc0, 0xc0, 0xc0, 0xe0, 0xe0, 0xe0, 0xc0, 0xc0, 0x80, 0x00, 0x00, 0x00, 0x00, 0x00, 0x00, 0x00, 0x00, 0x00, 0x00, 0x00, 0x00, 0x00, 0x00, 0x00, 0x00, 0x00, 0x00, 0x00, 0x00, 0x00, 0x00, 0x00, 0x00,
    0x00, 0x00, 0x00, 0x00, 0x00, 0x00, 0x00, 0x00, 0x00, 0x00, 0x00, 0x00, 0x00, 0x00, 0x00, 0x00, 0x00, 0x00, 0x00, 0x00, 0x00, 0x00, 0x00, 0xfe, 0xff, 0xff, 0xff, 0xff, 0xff, 0xf6, 0xe0, 0xcf, 0x9f, 0x1f, 0x3f, 0x3f, 0x3f, 0x7f, 0x7f, 0x7f, 0x7f, 0xff, 0xff, 0xff, 0xff, 0xff, 0xff, 0xff, 0xff, 0x7f, 0x7f, 0x7f, 0x3f, 0x3f, 0x3f, 0x9f, 0x9f, 0x3f, 0x3f, 0x7f, 0x7f, 0xff, 0x00, 0x00, 0x00, 0x00, 0x00, 0x00, 0x00, 0x00, 0x00, 0x00, 0x00, 0x00, 0x00, 0x00, 0x00, 0x00, 0x00, 0x00, 0x00, 0x00, 0x00, 0x00,
    0x00, 0x00, 0x00, 0x00, 0x00, 0x00, 0x00, 0x00, 0x00, 0x00, 0x00, 0x00, 0x00, 0x00, 0x00, 0x00, 0x00, 0x00, 0x00, 0x00, 0x00, 0x00, 0x00, 0x01, 0x01, 0x07, 0x07, 0x0f, 0x1f, 0x3f, 0x7f, 0xff, 0xff, 0xff, 0xff, 0xfc, 0xf8, 0xf0, 0xc0, 0x00, 0x00, 0x00, 0x00, 0x00, 0x00, 0x00, 0x00, 0x80, 0xe0, 0xf0, 0xf8, 0xfc, 0xfc, 0xfe, 0xff, 0xff, 0x3f, 0x3f, 0x1f, 0x0e, 0x06, 0x00, 0x00, 0x00, 0x00, 0x00, 0x00, 0x00, 0x00, 0x00, 0x00, 0x00, 0x00, 0x00, 0x00, 0x00, 0x00, 0x00, 0x00, 0x00, 0x00, 0x00, 0x00, 0x00,
    0x00, 0x00, 0x00, 0x00, 0x00, 0x00, 0x00, 0x00, 0x00, 0x00, 0x00, 0x00, 0x00, 0x00, 0x00, 0x00, 0x00, 0x00, 0x00, 0x00, 0x00, 0x00, 0x00, 0x00, 0x00, 0x00, 0x00, 0x00, 0x00, 0x00, 0x00, 0x00, 0x03, 0x0f, 0x7f, 0xff, 0xff, 0xff, 0xff, 0xff, 0xf8, 0x80, 0x00, 0x00, 0xe0, 0xf8, 0xff, 0xff, 0xff, 0xff, 0xff, 0x7f, 0x0f, 0x03, 0x01, 0x00, 0x00, 0x00, 0x00, 0x00, 0x00, 0x00, 0x00, 0x00, 0x00, 0x00, 0x00, 0x00, 0x00, 0x00, 0x00, 0x00, 0x00, 0x00, 0x00, 0x00, 0x00, 0x00, 0x00, 0x00, 0x00, 0x00, 0x00, 0x00,
    0x00, 0x00, 0x00, 0x00, 0x00, 0x00, 0x00, 0x00, 0x00, 0x00, 0x00, 0x00, 0x00, 0x00, 0x00, 0x00, 0x00, 0x00, 0x00, 0x00, 0x00, 0x00, 0x00, 0x00, 0x00, 0x00, 0x00, 0x00, 0x00, 0x00, 0x00, 0x00, 0x00, 0x00, 0x00, 0x07, 0x3f, 0x9f, 0x9f, 0xcf, 0xcf, 0xe7, 0xf8, 0xfe, 0xff, 0xff, 0xff, 0xff, 0xff, 0xff, 0x07, 0x00, 0x00, 0x00, 0x00, 0x00, 0x00, 0x00, 0x00, 0x00, 0x00, 0x00, 0x00, 0x00, 0x00, 0x00, 0x00, 0x00, 0x00, 0x00, 0x00, 0x00, 0x00, 0x00, 0x00, 0x00, 0x00, 0x00, 0x00, 0x00, 0x00, 0x00, 0x00, 0x00,
    0x00, 0x00, 0x00, 0x00, 0x00, 0x00, 0x00, 0x00, 0x00, 0x00, 0x00, 0x00, 0x00, 0x00, 0x00, 0x00, 0x00, 0x00, 0x00, 0x00, 0x00, 0x00, 0x00, 0x00, 0x00, 0x00, 0x00, 0x00, 0x00, 0x00, 0x00, 0x00, 0x00, 0x00, 0x00, 0x00, 0x00, 0x01, 0x01, 0x03, 0x03, 0x03, 0x07, 0x07, 0x03, 0x03, 0x01, 0x01, 0x00, 0x00, 0x00, 0x00, 0x00, 0x00, 0x00, 0x00, 0x00, 0x00, 0x00, 0x00, 0x00, 0x00, 0x00, 0x00, 0x00, 0x00, 0x00, 0x00, 0x00, 0x00, 0x00, 0x00, 0x00, 0x00, 0x00, 0x00, 0x00, 0x00, 0x00, 0x00, 0x00, 0x00, 0x00, 0x00};

const unsigned char ETU_6[] = {
    0x00, 0x00, 0x00, 0x00, 0x00, 0x00, 0x00, 0x00, 0x00, 0x00, 0x00, 0x00, 0x00, 0x00, 0x00, 0x00, 0x00, 0x00, 0x00, 0x00, 0x00, 0x00, 0x00, 0x00, 0x00, 0x00, 0x00, 0x00, 0xfe, 0xfc, 0xfc, 0xfc, 0xf8, 0xf8, 0xf8, 0xf0, 0xf0, 0xf0, 0xf0, 0xf0, 0xf0, 0xf0, 0xf0, 0xf0, 0xf0, 0xf8, 0xf8, 0xf8, 0xfc, 0xfc, 0xfc, 0xfe, 0xfe, 0xfe, 0xfc, 0xfc, 0xf8, 0xf8, 0xf0, 0x00, 0x00, 0x00, 0x00, 0x00, 0x00, 0x00, 0x00, 0x00, 0x00, 0x00, 0x00, 0x00, 0x00, 0x00, 0x00, 0x00, 0x00, 0x00, 0x00, 0x00, 0x00, 0x00, 0x00, 0x00,
    0x00, 0x00, 0x00, 0x00, 0x00, 0x00, 0x80, 0x00, 0x00, 0x00, 0x00, 0x00, 0x00, 0x00, 0x00, 0x00, 0x00, 0x00, 0x00, 0x00, 0x00, 0x00, 0x00, 0x00, 0x00, 0x00, 0x00, 0x00, 0x00, 0x81, 0x01, 0x01, 0x03, 0x03, 0x07, 0x07, 0x07, 0x87, 0x0f, 0x0f, 0x0f, 0x0f, 0x0f, 0x0f, 0x0f, 0x0f, 0x07, 0x07, 0x07, 0x03, 0x03, 0x03, 0x01, 0x01, 0x03, 0x03, 0x07, 0x07, 0x0f, 0x00, 0x00, 0x00, 0x00, 0x00, 0x00, 0x00, 0x00, 0x00, 0x00, 0x00, 0x00, 0x00, 0x00, 0x00, 0x00, 0x00, 0x00, 0x00, 0x00, 0x00, 0x00, 0x00, 0x00, 0x00,
    0x00, 0xf8, 0xfc, 0xfe, 0xfe, 0xff, 0xff, 0xd5, 0x80, 0x00, 0x00, 0x00, 0x00, 0x00, 0x00, 0x00, 0x00, 0x00, 0x00, 0x00, 0x00, 0x00, 0x00, 0x00, 0x00, 0x00, 0xe0, 0x3c, 0x33, 0x03, 0x3e, 0xe0, 0x80, 0x00, 0xe0, 0x3c, 0x17, 0x21, 0x1e, 0x70, 0x80, 0x00, 0x00, 0x00, 0x00, 0x00, 0x00, 0x00, 0x00, 0x00, 0x00, 0x00, 0x00, 0x00, 0x00, 0x00, 0x00, 0x00, 0x00, 0x00, 0x00, 0x00, 0x00, 0x00, 0x00, 0x00, 0x00, 0x00, 0x00, 0x00, 0x00, 0x00, 0x00, 0x80, 0xc0, 0xe0, 0xe0, 0xf0, 0xf0, 0xe0, 0xe0, 0xc0, 0xc0, 0x00,
    0x00, 0x07, 0x0f, 0x0f, 0x1f, 0x3f, 0x7f, 0xff, 0xff, 0xff, 0xfe, 0xfe, 0xf8, 0xf8, 0xe0, 0xc0, 0x00, 0x00, 0x00, 0x00, 0x00, 0x00, 0x00, 0x00, 0x00, 0x00, 0x00, 0x00, 0xc0, 0x80, 0x00, 0x00, 0x00, 0x00, 0xc0, 0x00, 0x00, 0x00, 0x00, 0x00, 0x00, 0x80, 0x80, 0x00, 0x00, 0x00, 0x00, 0x00, 0x00, 0x00, 0x00, 0x00, 0x00, 0x00, 0x80, 0x80, 0x00, 0x00, 0x00, 0x00, 0x00, 0x00, 0x00, 0x00, 0x00, 0x00, 0x00, 0x80, 0xe0, 0xf8, 0xfc, 0xfe, 0xff, 0xff, 0xff, 0x7f, 0x3f, 0x0f, 0x07, 0x03, 0x01, 0x01, 0x00, 0x00,
    0x00, 0x00, 0x00, 0x00, 0x00, 0x00, 0x00, 0x00, 0x01, 0x07, 0x0f, 0x3f, 0xff, 0xff, 0xff, 0xff, 0xff, 0xfc, 0xf0, 0x00, 0x00, 0x00, 0x00, 0x00, 0x00, 0x40, 0x78, 0x1e, 0x11, 0x08, 0x1f, 0x70, 0x40, 0x00, 0x7f, 0x00, 0x10, 0x3e, 0x43, 0x40, 0x42, 0x7f, 0x28, 0x00, 0x56, 0x16, 0x00, 0x7e, 0x42, 0x02, 0x03, 0x56, 0x24, 0x00, 0x49, 0x4e, 0x00, 0x00, 0x00, 0x00, 0x00, 0x00, 0x00, 0x00, 0x00, 0xe0, 0xfc, 0xff, 0xff, 0xff, 0xff, 0xff, 0x7f, 0x07, 0x01, 0x00, 0x00, 0x00, 0x00, 0x00, 0x00, 0x00, 0x00, 0x00,
    0x00, 0x00, 0x00, 0x00, 0x00, 0x00, 0x00, 0x00, 0x00, 0x00, 0x00, 0x00, 0x00, 0x1f, 0xff, 0x7f, 0x7f, 0x3f, 0x3f, 0x1e, 0x00, 0x00, 0x00, 0x00, 0x00, 0x00, 0x00, 0x00, 0x00, 0x00, 0x00, 0x00, 0x00, 0x00, 0x00, 0x00, 0x00, 0x00, 0x00, 0x00, 0x00, 0x00, 0x00, 0x00, 0x00, 0x00, 0x00, 0x00, 0x00, 0x00, 0x00, 0x00, 0x00, 0x00, 0x00, 0x00, 0x00, 0x00, 0x00, 0x30, 0x30, 0x78, 0x7c, 0x7c, 0xff, 0xff, 0x7f, 0x3f, 0x3f, 0x1f, 0x1f, 0x0f, 0x00, 0x00, 0x00, 0x00, 0x00, 0x00, 0x00, 0x00, 0x00, 0x00, 0x00, 0x00};

// [13] = Center_Left
// [14] = Center_Right
// Comparing [13] symbols of different arrays shows what will happen.
// #endregion

// #region Row Combinations

// 0 represents empty, 1 represents jumpable barrier, 2 represents non-jumpable barrier
/* Why predefined combinations?
** 1. To avoid the complexity of generating combinations.
** 2. There are a max of 27 combinations, which is not a big number.
** 3. Some combinations are impossible, and some require too many jumps to complete. Defining them in advance enables us to filter them out if needed in the logic.
*/
int row_combinations[81] = {
    // LEVEL 1: Combinations below this line might require 1 jumps to complete.
    0, 0, 0,
    0, 0, 2,
    0, 0, 1,
    0, 2, 0,
    0, 2, 1,
    0, 1, 0,
    0, 1, 2,
    0, 1, 1,
    2, 0, 0,
    2, 0, 2,
    2, 0, 1,
    1, 0, 0,
    1, 0, 2,
    1, 0, 1,
    1, 2, 0,
    1, 1, 0,
    1, 1, 1,
    // LEVEL 2: Combinations below this line might require 2 jumps to complete.
    0, 2, 2,
    2, 2, 0,
    2, 1, 0,
    2, 1, 2,
    2, 1, 1,
    1, 2, 1,
    1, 1, 2,
    // LEVEL 3: Combinations below this line might require 3 jumps to complete.
    2, 2, 1,
    1, 2, 2,
    // IMPOSSIBLE: {2, 2, 2} is the only combination that is not possible.
    2, 2, 2};
int level1_combinations[18][3] = {
    {0, 0, 0},
    {0, 0, 2},
    {0, 0, 1},
    {0, 2, 0},
    {0, 2, 1},
    {0, 1, 0},
    {0, 1, 2},
    {0, 1, 1},
    {2, 0, 0},
    {2, 0, 2},
    {2, 0, 1},
    {1, 0, 0},
    {1, 0, 2},
    {1, 0, 1},
    {1, 2, 0},
    {1, 1, 0},
    {1, 1, 1},
};
// #endregion Row Combinations

volatile uint8_t timer_expired = 0;

/* USER CODE END PV */

void SystemClock_Config(void);
static void MX_GPIO_Init(void);
static void MX_TIM3_Init(void);
/* USER CODE BEGIN PFP */
char Read_KeyPad(void)
{
  HAL_GPIO_WritePin(C1_PORT, C1_PIN, GPIO_PIN_RESET);
  HAL_GPIO_WritePin(C2_PORT, C2_PIN, GPIO_PIN_SET);
  HAL_GPIO_WritePin(C3_PORT, C3_PIN, GPIO_PIN_SET);
  HAL_GPIO_WritePin(C4_PORT, C4_PIN, GPIO_PIN_SET);

  /*   if (!(HAL_GPIO_ReadPin(R1_PORT, R1_PIN)))
    {
      while (!(HAL_GPIO_ReadPin(R1_PORT, R1_PIN)))
        ;
      return '1';
    } */

  if (!(HAL_GPIO_ReadPin(R2_PORT, R2_PIN)))
  {
    while (!(HAL_GPIO_ReadPin(R2_PORT, R2_PIN)))
      ;
    return '4';
  }
  /*
    if (!(HAL_GPIO_ReadPin(R3_PORT, R3_PIN)))
    {
      while (!(HAL_GPIO_ReadPin(R3_PORT, R3_PIN)))
        ;
      return '7';
    }

    if (!(HAL_GPIO_ReadPin(R4_PORT, R4_PIN)))
    {
      while (!(HAL_GPIO_ReadPin(R4_PORT, R4_PIN)))
        ;
      return '*';
    } */

  HAL_GPIO_WritePin(C1_PORT, C1_PIN, GPIO_PIN_SET);
  HAL_GPIO_WritePin(C2_PORT, C2_PIN, GPIO_PIN_RESET);
  HAL_GPIO_WritePin(C3_PORT, C3_PIN, GPIO_PIN_SET);
  HAL_GPIO_WritePin(C4_PORT, C4_PIN, GPIO_PIN_SET);

  /* if (!(HAL_GPIO_ReadPin(R1_PORT, R1_PIN)))
  {
    while (!(HAL_GPIO_ReadPin(R1_PORT, R1_PIN)))
      ;
    return '2';
  } */

  if (!(HAL_GPIO_ReadPin(R2_PORT, R2_PIN)))
  {
    while (!(HAL_GPIO_ReadPin(R2_PORT, R2_PIN)))
      ;
    return '5';
  }

  /*   if (!(HAL_GPIO_ReadPin(R3_PORT, R3_PIN)))
    {
      while (!(HAL_GPIO_ReadPin(R3_PORT, R3_PIN)))
        ;
      return '8';
    }

    if (!(HAL_GPIO_ReadPin(R4_PORT, R4_PIN)))
    {
      while (!(HAL_GPIO_ReadPin(R4_PORT, R4_PIN)))
        ;
      return '0';
    } */

  HAL_GPIO_WritePin(C1_PORT, C1_PIN, GPIO_PIN_SET);
  HAL_GPIO_WritePin(C2_PORT, C2_PIN, GPIO_PIN_SET);
  HAL_GPIO_WritePin(C3_PORT, C3_PIN, GPIO_PIN_RESET);
  HAL_GPIO_WritePin(C4_PORT, C4_PIN, GPIO_PIN_SET);

  /*   if (!(HAL_GPIO_ReadPin(R1_PORT, R1_PIN)))
    {
      while (!(HAL_GPIO_ReadPin(R1_PORT, R1_PIN)))
        ;
      return '3';
    }
   */
  if (!(HAL_GPIO_ReadPin(R2_PORT, R2_PIN)))
  {
    while (!(HAL_GPIO_ReadPin(R2_PORT, R2_PIN)))
      ;
    return '6';
  }

  /* if (!(HAL_GPIO_ReadPin(R3_PORT, R3_PIN)))
  {
    while (!(HAL_GPIO_ReadPin(R3_PORT, R3_PIN)))
      ;
    return '9';
  }

  if (!(HAL_GPIO_ReadPin(R4_PORT, R4_PIN)))
  {
    while (!(HAL_GPIO_ReadPin(R4_PORT, R4_PIN)))
      ;
    return '*';
  } */

  /*   HAL_GPIO_WritePin(C1_PORT, C1_PIN, GPIO_PIN_SET);
    HAL_GPIO_WritePin(C2_PORT, C2_PIN, GPIO_PIN_SET);
    HAL_GPIO_WritePin(C3_PORT, C3_PIN, GPIO_PIN_SET);
    HAL_GPIO_WritePin(C4_PORT, C4_PIN, GPIO_PIN_RESET);

    if (!(HAL_GPIO_ReadPin(R1_PORT, R1_PIN)))
    {
      while (!(HAL_GPIO_ReadPin(R1_PORT, R1_PIN)))
        ;
      return 'A';
    }

    if (!(HAL_GPIO_ReadPin(R2_PORT, R2_PIN)))
    {
      while (!(HAL_GPIO_ReadPin(R2_PORT, R2_PIN)))
        ;
      return 'B';
    }

    if (!(HAL_GPIO_ReadPin(R3_PORT, R3_PIN)))
    {
      while (!(HAL_GPIO_ReadPin(R3_PORT, R3_PIN)))
        ;
      return 'C';
    }

    if (!(HAL_GPIO_ReadPin(R4_PORT, R4_PIN)))
    {
      while (!(HAL_GPIO_ReadPin(R4_PORT, R4_PIN)))
        ;
      return 'D';
    } */

  return 0;
}

/* USER CODE END PFP */

int main(void)
{

  /* MCU Configuration--------------------------------------------------------*/

  /* Reset of all peripherals, Initializes the Flash interface and the Systick. */
  HAL_Init();

  /* Configure the system clock */
  SystemClock_Config();

  /* Initialize all configured peripherals */
  MX_GPIO_Init();
  MX_TIM3_Init();
  /* USER CODE BEGIN 2 */
  NOKIA_Init();
  // We are creating our random images even before the game starts.
  // This gives us more free memory to work with during gameplay.
  int player_position = 0;
  int is_jumping = 0;
  const int rows = 25;
  int level = 1;
  int current_iteration = 0;
  int crash = 0;
  char inputKey = 0;

  int random_index = 0;

  int screen[6][3] = {
      {0, 0, 0},
      {0, 0, 0},
      {0, 0, 0},
      {0, 0, 0},
      {0, 0, 0},
      {0, 0, 0}};

  NOKIA_Image(Screen_Start_Bitmap);

  HAL_Delay(700);

  int game_state = 0;
  /* USER CODE END 2 */

  /* Infinite loop */
  while (1)
  {

    /* USER CODE BEGIN 3 */
    if (game_state)
    {
      for (current_iteration = 0; current_iteration < rows; current_iteration++)
      {
        if (current_iteration == 0)
        {
          NOKIA_Partial_Image(5, 0, 28, 28, Player_Default_Bitmap);
        }
        timer_expired = 0;
        HAL_TIM_Base_Start_IT(&htim3);

        // Unjump the character
        is_jumping = 0;
        // Clear row
        NOKIA_Partial_Image(5, 0, 84, 84, Empty_Row_Bitmap);
        // Readd Player
        NOKIA_Partial_Image(5, player_position * 28, 28, 28, Player_Default_Bitmap);

        while (!timer_expired)
        {
          inputKey = Read_KeyPad();
          // Receive inputs.
          if (inputKey == '4' && player_position > 0)
          {
            NOKIA_Partial_Image(5, player_position * 28, 28, 28, Empty_Bitmap);
            player_position--;
          }
          else if (inputKey == '6' && player_position < 2)
          {
            NOKIA_Partial_Image(5, player_position * 28, 28, 28, Empty_Bitmap);
            player_position++;
          }
          else if (inputKey == '5')
          {
            NOKIA_Partial_Image(5, player_position * 28, 28, 28, Empty_Bitmap);
            is_jumping = !is_jumping;
          }

          if (is_jumping)
          {
            NOKIA_Partial_Image(5, player_position * 28, 28, 28, Player_Jump_Bitmap);
          }
          else
          {
            NOKIA_Partial_Image(5, player_position * 28, 28, 28, Player_Default_Bitmap);
          }
        }

        // Shift array2 3 places to the left.
        for (int i = 5; i > 0; i--)
        {
          for (int j = 0; j < 3; j++)
          {
            screen[i][j] = screen[i - 1][j];
          }
        }

        // Replace the first 3 elements of array2 with a random row from array1.
        // Here, we use the rand() function to generate a random number between 0 and 16.
        random_index = rand() % 17;
        /*if(current_iteration%2==1){
        for (int j = 0; j < 3; j++)
        {
          screen[0][j] = level1_combinations[random_index][j];
        }
      }
        else{
        screen[0][0] = 0;
          screen[0][1] = 0;
          screen[0][2] = 0;
        }*/
        for (int j = 0; j < 3; j++)
        {
          screen[0][j] = level1_combinations[random_index][j];
        }

        // Using function NOKIA_Partial_Image, we can draw a partial image on the screen.
        // The first 2 arguments are the x (row) and y (pixel) coordinates of the top starting point.
        // The next 2 arguments are the width (in pixels) and size (in bytes) of the image.
        // The last argument is the image itself.
        // We will use this function to draw all the rows in "screen".
        for (int j = 0; j < 6; j++)
        {
          switch (screen[j][0])
          {
          case 0:
            NOKIA_Partial_Image(j, 0, 28, 28, Empty_Bitmap);
            break;
          case 1:
            NOKIA_Partial_Image(j, 0, 28, 28, Barrier_Jump_Bitmap);
            break;
          case 2:
            NOKIA_Partial_Image(j, 0, 28, 28, Barrier_Solid_Bitmap);
            break;
          }
          switch (screen[j][1])
          {
          case 0:
            NOKIA_Partial_Image(j, 28, 28, 28, Empty_Bitmap);
            break;
          case 1:
            NOKIA_Partial_Image(j, 28, 28, 28, Barrier_Jump_Bitmap);
            break;
          case 2:
            NOKIA_Partial_Image(j, 28, 28, 28, Barrier_Solid_Bitmap);
            break;
          }
          switch (screen[j][2])
          {
          case 0:
            NOKIA_Partial_Image(j, 56, 28, 28, Empty_Bitmap);
            break;
          case 1:
            NOKIA_Partial_Image(j, 56, 28, 28, Barrier_Jump_Bitmap);
            break;
          case 2:
            NOKIA_Partial_Image(j, 56, 28, 28, Barrier_Solid_Bitmap);
            break;
          }

          // NOKIA_Partial_Image(0, j * 8, 24, 3, screen[j]);
        }

        // Add the player to the screen
        if (is_jumping)
        {
          NOKIA_Partial_Image(5, player_position * 28, 28, 28, Player_Jump_Bitmap);
        }
        else
        {
          NOKIA_Partial_Image(5, player_position * 28, 28, 28, Player_Default_Bitmap);
        }

        // Check if the player has crashed.
        if (screen[5][player_position] == 2) // Solid Barrier
        {
          crash = 1;
        }
        else if (screen[5][player_position] == 1 && !is_jumping) // Jumpable Barrier, but not jumping
        {
          crash = 1;
        }

        if (crash)
          break;
      }
      // When loop ends (win) or breaks (crash), display animation.
      if (crash)
      {
        NOKIA_Image(Screen_End_Fail_Bitmap);
      }
      else
      {
        NOKIA_Image(ETU_1);
				HAL_Delay(400);
				NOKIA_Image(ETU_2);
				HAL_Delay(400);
				NOKIA_Image(ETU_3);
				HAL_Delay(400);
				NOKIA_Image(ETU_4);
				HAL_Delay(400);
				NOKIA_Image(ETU_5);
				HAL_Delay(400);
				NOKIA_Image(ETU_6);
				HAL_Delay(400);
      }
      // Wait 2 seconds
      HAL_Delay(5000);
      // Reset everything to initial state
      player_position = 0;
      is_jumping = 0;
      level = 1;
      current_iteration = 0;
      crash = 0;
      inputKey = 0;
      // Reset the screen array to all 0s
      for (int i = 0; i < 6; i++)
      {
        for (int j = 0; j < 3; j++)
        {
          screen[i][j] = 0;
        }
      }

      NOKIA_Image(Screen_Start_Bitmap);
      game_state = 0;
    }
    else
    {
      // If not in game state, this means we just started. We will reset all variables and show the welcome screen.
      if (Read_KeyPad() == '5')
      {
        // Display Empty Screen
        NOKIA_Clear();
        game_state = 1;
      }
    }
  }
  /* USER CODE END 3 */
}

void SystemClock_Config(void)
{
  RCC_OscInitTypeDef RCC_OscInitStruct = {0};
  RCC_ClkInitTypeDef RCC_ClkInitStruct = {0};

  /** Configure the main internal regulator output voltage
   */
  __HAL_RCC_PWR_CLK_ENABLE();
  __HAL_PWR_VOLTAGESCALING_CONFIG(PWR_REGULATOR_VOLTAGE_SCALE1);

  /** Initializes the RCC Oscillators according to the specified parameters
   * in the RCC_OscInitTypeDef structure.
   */
  RCC_OscInitStruct.OscillatorType = RCC_OSCILLATORTYPE_HSI;
  RCC_OscInitStruct.HSIState = RCC_HSI_ON;
  RCC_OscInitStruct.HSICalibrationValue = RCC_HSICALIBRATION_DEFAULT;
  RCC_OscInitStruct.PLL.PLLState = RCC_PLL_NONE;
  if (HAL_RCC_OscConfig(&RCC_OscInitStruct) != HAL_OK)
  {
    Error_Handler();
  }

  /** Initializes the CPU, AHB and APB buses clocks
   */
  RCC_ClkInitStruct.ClockType = RCC_CLOCKTYPE_HCLK | RCC_CLOCKTYPE_SYSCLK | RCC_CLOCKTYPE_PCLK1 | RCC_CLOCKTYPE_PCLK2;
  RCC_ClkInitStruct.SYSCLKSource = RCC_SYSCLKSOURCE_HSI;
  RCC_ClkInitStruct.AHBCLKDivider = RCC_SYSCLK_DIV1;
  RCC_ClkInitStruct.APB1CLKDivider = RCC_HCLK_DIV1;
  RCC_ClkInitStruct.APB2CLKDivider = RCC_HCLK_DIV1;

  if (HAL_RCC_ClockConfig(&RCC_ClkInitStruct, FLASH_LATENCY_0) != HAL_OK)
  {
    Error_Handler();
  }
}

static void MX_TIM3_Init(void)
{

  TIM_ClockConfigTypeDef sClockSourceConfig = {0};
  TIM_MasterConfigTypeDef sMasterConfig = {0};

  htim3.Instance = TIM3;
  htim3.Init.Prescaler = 999;
  htim3.Init.CounterMode = TIM_COUNTERMODE_UP;
  htim3.Init.Period = 23999;
  htim3.Init.ClockDivision = TIM_CLOCKDIVISION_DIV1;
  htim3.Init.AutoReloadPreload = TIM_AUTORELOAD_PRELOAD_DISABLE;
  if (HAL_TIM_Base_Init(&htim3) != HAL_OK)
  {
    Error_Handler();
  }
  sClockSourceConfig.ClockSource = TIM_CLOCKSOURCE_INTERNAL;
  if (HAL_TIM_ConfigClockSource(&htim3, &sClockSourceConfig) != HAL_OK)
  {
    Error_Handler();
  }
  sMasterConfig.MasterOutputTrigger = TIM_TRGO_RESET;
  sMasterConfig.MasterSlaveMode = TIM_MASTERSLAVEMODE_DISABLE;
  if (HAL_TIMEx_MasterConfigSynchronization(&htim3, &sMasterConfig) != HAL_OK)
  {
    Error_Handler();
  }
}

static void MX_GPIO_Init(void)
{
  GPIO_InitTypeDef GPIO_InitStruct = {0};

  /* GPIO Ports Clock Enable */
  __HAL_RCC_GPIOA_CLK_ENABLE();
  __HAL_RCC_GPIOC_CLK_ENABLE();
  __HAL_RCC_GPIOB_CLK_ENABLE();

  /*Configure GPIO pin Output Level */
  HAL_GPIO_WritePin(GPIOA, GPIO_PIN_4 | GPIO_PIN_5 | GPIO_PIN_7 | GPIO_PIN_13 | GPIO_PIN_14, GPIO_PIN_RESET);

  /*Configure GPIO pin Output Level */
  HAL_GPIO_WritePin(GPIOC, GPIO_PIN_5 | GPIO_PIN_10 | GPIO_PIN_11, GPIO_PIN_RESET);

  /*Configure GPIO pin Output Level */
  HAL_GPIO_WritePin(GPIOB, GPIO_PIN_10 | GPIO_PIN_11, GPIO_PIN_RESET);

  /*Configure GPIO pins : PA4 PA5 PA7 PA13
                           PA14 */
  GPIO_InitStruct.Pin = GPIO_PIN_4 | GPIO_PIN_5 | GPIO_PIN_7 | GPIO_PIN_13 | GPIO_PIN_14;
  GPIO_InitStruct.Mode = GPIO_MODE_OUTPUT_PP;
  GPIO_InitStruct.Pull = GPIO_NOPULL;
  GPIO_InitStruct.Speed = GPIO_SPEED_FREQ_LOW;
  HAL_GPIO_Init(GPIOA, &GPIO_InitStruct);

  /*Configure GPIO pins : PC5 PC10 PC11 */
  GPIO_InitStruct.Pin = GPIO_PIN_5 | GPIO_PIN_10 | GPIO_PIN_11;
  GPIO_InitStruct.Mode = GPIO_MODE_OUTPUT_PP;
  GPIO_InitStruct.Pull = GPIO_NOPULL;
  GPIO_InitStruct.Speed = GPIO_SPEED_FREQ_LOW;
  HAL_GPIO_Init(GPIOC, &GPIO_InitStruct);

  /*Configure GPIO pins : PB10 PB11 */
  GPIO_InitStruct.Pin = GPIO_PIN_10 | GPIO_PIN_11;
  GPIO_InitStruct.Mode = GPIO_MODE_OUTPUT_PP;
  GPIO_InitStruct.Pull = GPIO_NOPULL;
  GPIO_InitStruct.Speed = GPIO_SPEED_FREQ_LOW;
  HAL_GPIO_Init(GPIOB, &GPIO_InitStruct);

  /*Configure GPIO pins : PB14 PB15 PB6 PB7 */
  GPIO_InitStruct.Pin = GPIO_PIN_14 | GPIO_PIN_15 | GPIO_PIN_6 | GPIO_PIN_7;
  GPIO_InitStruct.Mode = GPIO_MODE_INPUT;
  GPIO_InitStruct.Pull = GPIO_PULLUP;
  HAL_GPIO_Init(GPIOB, &GPIO_InitStruct);
}

/* USER CODE BEGIN 4 */
void HAL_TIM_PeriodElapsedCallback(TIM_HandleTypeDef *htim)
{
  timer_expired = 1;
}
/* USER CODE END 4 */

void Error_Handler(void)
{
  __disable_irq();
  while (1)
  {
  }
}
